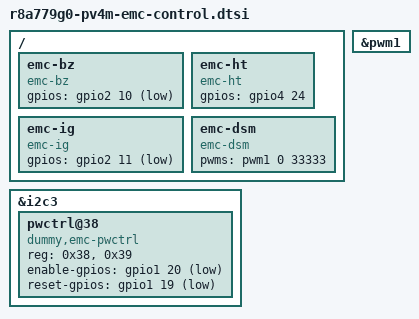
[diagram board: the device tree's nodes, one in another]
#include <dt-bindings/gpio/gpio.h>

/ {
	emc-bz {
		compatible = "emc-bz";
		gpios = <&gpio2 10 GPIO_ACTIVE_LOW>;
	};
};

/ {
	emc-ht {
		compatible = "emc-ht";
		gpios = <&gpio4 24 GPIO_ACTIVE_HIGH>;
	};
};

/ {
	emc-ig {
		compatible = "emc-ig";
		gpios = <&gpio2 11 GPIO_ACTIVE_LOW>;
	};
};

&pwm1 {
	status = "okay";
};

/ {
	emc-dsm {
		compatible = "emc-dsm";
		pwms = <&pwm1 0 33333>;		/* 30kHz = 33333.333... (ns) */
	};
};

&i2c3 {
	pwctrl@38 {
		compatible = "dummy,emc-pwctrl";
		#address-cells = <1>;
		#size-cells = <0>;
		reg = <0x38>, <0x39>;
		status = "okay";
		enable-gpios = <&gpio1 20 GPIO_ACTIVE_LOW>;	/* EN_V4M-DESLDO_1R8V 	 */
		reset-gpios = <&gpio1 19 GPIO_ACTIVE_LOW>;	/* RESET_DESLDO-V4M_1R8V */
	};
};
